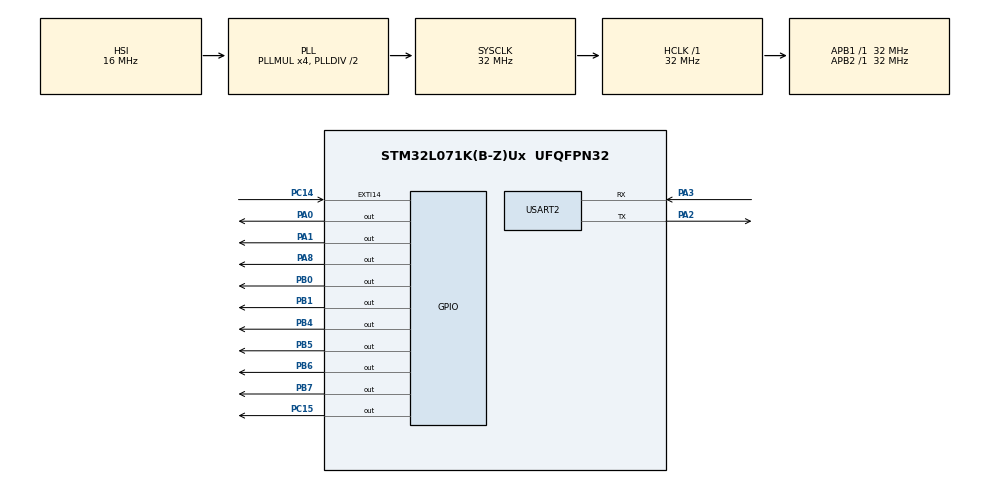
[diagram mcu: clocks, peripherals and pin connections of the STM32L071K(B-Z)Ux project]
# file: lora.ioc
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Mcu.Family=STM32L0
Mcu.Name=STM32L071K(B-Z)Ux
Mcu.Package=UFQFPN32
NVIC.EXTI4_15_IRQn=true\:0\:0\:false\:false\:true\:true\:true
NVIC.USART2_IRQn=true\:0\:0\:false\:false\:true\:true\:true
PA0.Signal=GPIO_Output
PA1.Signal=GPIO_Output
PA13.Mode=Serial_Wire
PA13.Signal=SYS_SWDIO
PA14.Mode=Serial_Wire
PA14.Signal=SYS_SWCLK
PA2.Mode=Asynchronous
PA2.Signal=USART2_TX
PA3.Mode=Asynchronous
PA3.Signal=USART2_RX
PA8.GPIO_PuPd=GPIO_PULLDOWN
PA8.PinState=GPIO_PIN_SET
PA8.Signal=GPIO_Output
PB0.GPIO_PuPd=GPIO_PULLDOWN
PB0.Signal=GPIO_Output
PB1.GPIO_PuPd=GPIO_PULLDOWN
PB1.Signal=GPIO_Output
PB4.Signal=GPIO_Output
PB5.Signal=GPIO_Output
PB6.Signal=GPIO_Output
PB7.Signal=GPIO_Output
PC14-OSC32_IN.GPIO_PuPd=GPIO_PULLUP
PC14-OSC32_IN.Signal=GPXTI14
PC15-OSC32_OUT.Signal=GPIO_Output
ProjectManager.HeapSize=0x200
ProjectManager.StackSize=0x400
ProjectManager.TargetToolchain=MDK-ARM V5
RCC.AHBFreq_Value=32000000
RCC.APB1Freq_Value=32000000
RCC.APB1TimFreq_Value=32000000
RCC.APB2Freq_Value=32000000
RCC.APB2TimFreq_Value=32000000
RCC.HCLKFreq_Value=32000000
RCC.HSI16_VALUE=16000000
RCC.HSI_VALUE=16000000
RCC.LSE_VALUE=32768
RCC.MSI_VALUE=2097000
RCC.PLLMUL=RCC_PLLMUL_4
RCC.SYSCLKFreq_VALUE=32000000
RCC.SYSCLKSource=RCC_SYSCLKSOURCE_PLLCLK
RCC.VCOOutputFreq_Value=64000000
USART2.VirtualMode-Asynchronous=VM_ASYNC
board=custom

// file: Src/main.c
/* USER CODE BEGIN Header */
/**
  ******************************************************************************
  * @file           : main.c
  * @brief          : Main program body
  ******************************************************************************
  * @attention
  *
  * <h2><center>&copy; Copyright (c) 2021 STMicroelectronics.
  * All rights reserved.</center></h2>
  *
  * This software component is licensed by ST under BSD 3-Clause license,
  * the "License"; You may not use this file except in compliance with the
  * License. You may obtain a copy of the License at:
  *                        opensource.org/licenses/BSD-3-Clause
  *
  ******************************************************************************
  */
/* USER CODE END Header */
#include "main.h"
#include "usart.h"
#include "gpio.h"

/* USER CODE BEGIN Includes */
#include "oled.h"
#include "stdio.h"
#include "app.h"

/* USER CODE END Includes */

void SystemClock_Config(void);

int main(void)
{

  /* MCU Configuration--------------------------------------------------------*/

  /* Reset of all peripherals, Initializes the Flash interface and the Systick. */
  HAL_Init();

  /* Configure the system clock */
  SystemClock_Config();

  /* Initialize all configured peripherals */
  MX_GPIO_Init();
  MX_USART2_UART_Init();
  /* USER CODE BEGIN 2 */
	user_oled_init();

  /* USER CODE END 2 */

  /* Infinite loop */
  /* USER CODE BEGIN WHILE */
  while (1)
  {
		user_loop();
    /* USER CODE END WHILE */

  }
}

void SystemClock_Config(void)
{
  RCC_OscInitTypeDef RCC_OscInitStruct = {0};
  RCC_ClkInitTypeDef RCC_ClkInitStruct = {0};
  RCC_PeriphCLKInitTypeDef PeriphClkInit = {0};

  /** Configure the main internal regulator output voltage
  */
  __HAL_PWR_VOLTAGESCALING_CONFIG(PWR_REGULATOR_VOLTAGE_SCALE1);
  /** Initializes the RCC Oscillators according to the specified parameters
  * in the RCC_OscInitTypeDef structure.
  */
  RCC_OscInitStruct.OscillatorType = RCC_OSCILLATORTYPE_HSI;
  RCC_OscInitStruct.HSIState = RCC_HSI_ON;
  RCC_OscInitStruct.HSICalibrationValue = RCC_HSICALIBRATION_DEFAULT;
  RCC_OscInitStruct.PLL.PLLState = RCC_PLL_ON;
  RCC_OscInitStruct.PLL.PLLSource = RCC_PLLSOURCE_HSI;
  RCC_OscInitStruct.PLL.PLLMUL = RCC_PLLMUL_4;
  RCC_OscInitStruct.PLL.PLLDIV = RCC_PLLDIV_2;
  if (HAL_RCC_OscConfig(&RCC_OscInitStruct) != HAL_OK)
  {
    Error_Handler();
  }
  /** Initializes the CPU, AHB and APB buses clocks
  */
  RCC_ClkInitStruct.ClockType = RCC_CLOCKTYPE_HCLK|RCC_CLOCKTYPE_SYSCLK
                              |RCC_CLOCKTYPE_PCLK1|RCC_CLOCKTYPE_PCLK2;
  RCC_ClkInitStruct.SYSCLKSource = RCC_SYSCLKSOURCE_PLLCLK;
  RCC_ClkInitStruct.AHBCLKDivider = RCC_SYSCLK_DIV1;
  RCC_ClkInitStruct.APB1CLKDivider = RCC_HCLK_DIV1;
  RCC_ClkInitStruct.APB2CLKDivider = RCC_HCLK_DIV1;

  if (HAL_RCC_ClockConfig(&RCC_ClkInitStruct, FLASH_LATENCY_1) != HAL_OK)
  {
    Error_Handler();
  }
  PeriphClkInit.PeriphClockSelection = RCC_PERIPHCLK_USART2;
  PeriphClkInit.Usart2ClockSelection = RCC_USART2CLKSOURCE_PCLK1;
  if (HAL_RCCEx_PeriphCLKConfig(&PeriphClkInit) != HAL_OK)
  {
    Error_Handler();
  }
}

/* USER CODE BEGIN 4 */

int fputc(int ch, FILE *f)
{
  HAL_UART_Transmit(&huart2, (uint8_t *)&ch, 1, 0xffff);
  return ch;
}

/* USER CODE END 4 */

void Error_Handler(void)
{
  __disable_irq();
  while (1)
  {
  }
}

/************************ (C) COPYRIGHT STMicroelectronics *****END OF FILE****/
